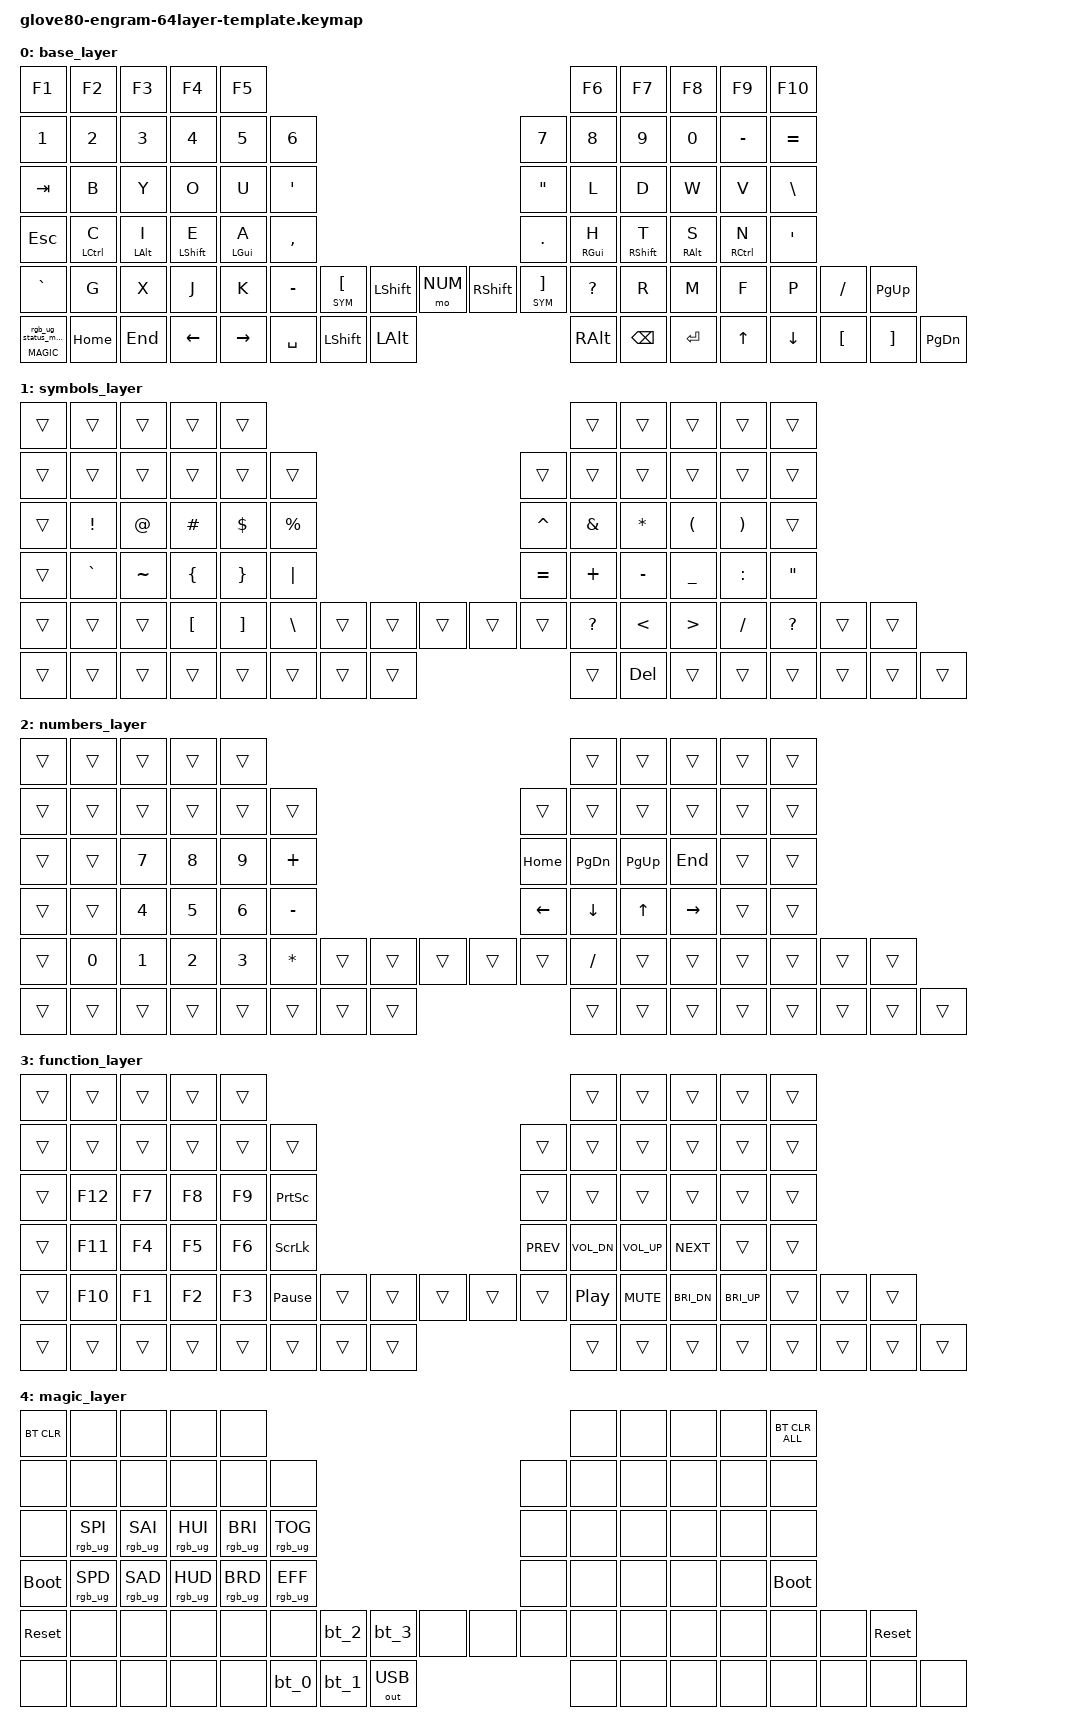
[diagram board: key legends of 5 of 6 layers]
/*
 * Glove80 Engram Layout with 64-Layer Support
 * Template for glove80-keymaps repo generation
 *
 * This template is designed to be:
 * 1. Generated/modified in glove80-keymaps repo using sunaku workflow
 * 2. Copied to zmk firmware repo at: app/boards/arm/glove80/glove80.keymap
 * 3. Built with 64-layer capable firmware
 *
 * WORKFLOW:
 * - Edit/generate in glove80-keymaps repo (with templating + PDF generation)
 * - Copy generated DTSI to ZMK firmware repo
 * - Build with: nix-build -A glove80_combined
 *
 * COMPATIBILITY:
 * - Works with MoErgo web configurator format
 * - Supports up to 64 layers (layers 0-63)
 * - Preserves factory behaviors for bootloader/reset access
 */

#include <behaviors.dtsi>
#include <dt-bindings/zmk/keys.h>
#include <dt-bindings/zmk/bt.h>
#include <dt-bindings/zmk/ext_power.h>
#include <dt-bindings/zmk/outputs.h>
#include <dt-bindings/zmk/rgb.h>

// Layer definitions - Engram optimized
#define BASE     0  // Engram base layer
#define SYM      1  // Symbols layer
#define NUM      2  // Numbers/navigation layer
#define FN       3  // Function keys
#define MAGIC    4  // System: Bootloader, reset, RGB, Bluetooth

// Example extended layers (you can use up to layer 63!)
#define GREEK    5  // Greek letters (example)
#define MATH     6  // Math symbols (example)
#define MEDIA    7  // Media controls (example)
// ... define up to layer 63 as needed

/ {
    /*
     * BEHAVIORS
     * Define custom behaviors for your layout
     */
    behaviors {
        // Home row mods - balanced for Engram
        hml: homerow_mods_left {
            compatible = "zmk,behavior-hold-tap";
            #binding-cells = <2>;
            flavor = "balanced";
            tapping-term-ms = <280>;
            quick-tap-ms = <175>;
            require-prior-idle-ms = <150>;
            bindings = <&kp>, <&kp>;
            hold-trigger-key-positions = <
                // Right hand keys (allow left hand mods)
                5 6 7 8 9
                15 16 17 18 19 20
                25 26 27 28 29 30
                35 36 37 38 39 40
                50 51 52 53 54 55
                60 61 62 63 64 65
                69 70 71 72 73 74 75 76 77 78 79
            >;
        };

        hmr: homerow_mods_right {
            compatible = "zmk,behavior-hold-tap";
            #binding-cells = <2>;
            flavor = "balanced";
            tapping-term-ms = <280>;
            quick-tap-ms = <175>;
            require-prior-idle-ms = <150>;
            bindings = <&kp>, <&kp>;
            hold-trigger-key-positions = <
                // Left hand keys (allow right hand mods)
                0 1 2 3 4
                10 11 12 13 14
                21 22 23 24
                31 32 33 34
                41 42 43 44 45 46 47 48 49
                56 57 58 59
                66 67 68
            >;
        };

        // Layer tap for symbol/number access
        ltq: layer_tap_quick {
            compatible = "zmk,behavior-hold-tap";
            #binding-cells = <2>;
            flavor = "balanced";
            tapping-term-ms = <200>;
            quick-tap-ms = <150>;
            bindings = <&mo>, <&kp>;
        };

        // Magic layer access (for system functions)
        magic: magic_hold_tap {
            compatible = "zmk,behavior-hold-tap";
            #binding-cells = <2>;
            flavor = "tap-preferred";
            tapping-term-ms = <200>;
            bindings = <&mo>, <&rgb_ug_status_macro>;
        };
    };

    /*
     * MACROS
     * Define macros for common operations
     */
    macros {
        // RGB status display
        rgb_ug_status_macro: rgb_ug_status_macro_0 {
            compatible = "zmk,behavior-macro";
            #binding-cells = <0>;
            bindings = <&rgb_ug RGB_STATUS>;
        };

        // Bluetooth profile selection macros
        bt_0: bt_profile_macro_0 {
            compatible = "zmk,behavior-macro";
            #binding-cells = <0>;
            bindings = <&out OUT_BLE>, <&bt BT_SEL 0>;
        };

        bt_1: bt_profile_macro_1 {
            compatible = "zmk,behavior-macro";
            #binding-cells = <0>;
            bindings = <&out OUT_BLE>, <&bt BT_SEL 1>;
        };

        bt_2: bt_profile_macro_2 {
            compatible = "zmk,behavior-macro";
            #binding-cells = <0>;
            bindings = <&out OUT_BLE>, <&bt BT_SEL 2>;
        };

        bt_3: bt_profile_macro_3 {
            compatible = "zmk,behavior-macro";
            #binding-cells = <0>;
            bindings = <&out OUT_BLE>, <&bt BT_SEL 3>;
        };
    };

    /*
     * KEYMAP
     * Engram layout with 64-layer support
     */
    keymap {
        compatible = "zmk,keymap";

        // =================================================================
        // LAYER 0: BASE (Engram)
        // =================================================================
        /*
         * Engram Layout:
         * https://engram.dev/
         *
         *     b  y  o  u  '     "  l  d  w  v
         *     c  i  e  a  ,     .  h  t  s  n
         *     g  x  j  k  -     ?  r  m  f  p
         *        ␣  ⇧  ⎇        ⎈  ⌫  ↵
         *
         * With home row mods:
         * Left:  C(c) A(i) S(e) G(a)
         * Right: G(h) S(t) A(s) C(n)
         */
        base_layer {
            bindings = <
            // Top row (F-keys remain for compatibility)
            &kp F1         &kp F2          &kp F3          &kp F4          &kp F5                                                                                                      &kp F6          &kp F7          &kp F8          &kp F9          &kp F10
            // Number row
            &kp N1         &kp N2          &kp N3          &kp N4          &kp N5          &kp N6                                                                          &kp N7          &kp N8          &kp N9          &kp N0          &kp MINUS       &kp EQUAL
            // Top letter row: B Y O U '  |  " L D W V
            &kp TAB        &kp B           &kp Y           &kp O           &kp U           &kp SQT                                                                         &kp DQT         &kp L           &kp D           &kp W           &kp V           &kp BSLH
            // Home row: C I E A ,  |  . H T S N (with home row mods)
            &kp ESC        &hml LCTRL C    &hml LALT I     &hml LSHFT E    &hml LGUI A     &kp COMMA                                                                       &kp DOT         &hmr RGUI H     &hmr RSHFT T    &hmr RALT S     &hmr RCTRL N    &kp SQT
            // Bottom row: G X J K -  |  ? R M F P
            &kp GRAVE      &kp G           &kp X           &kp J           &kp K           &kp MINUS       &ltq SYM LBKT   &kp LSHFT       &mo NUM         &kp RSHFT       &ltq SYM RBKT   &kp QMARK       &kp R           &kp M           &kp F           &kp P           &kp FSLH        &kp PG_UP
            // Thumb cluster
            &magic MAGIC 0 &kp HOME        &kp END         &kp LEFT        &kp RIGHT                       &kp SPACE       &kp LSHFT       &kp LALT        &kp RALT        &kp BSPC        &kp RET                                         &kp UP          &kp DOWN        &kp LBKT        &kp RBKT        &kp PG_DN
            >;
        };

        // =================================================================
        // LAYER 1: SYMBOLS
        // =================================================================
        /*
         * Optimized symbol layer for programming
         */
        symbols_layer {
            bindings = <
            &trans         &trans          &trans          &trans          &trans                                                                                                      &trans          &trans          &trans          &trans          &trans
            &trans         &trans          &trans          &trans          &trans          &trans                                                                          &trans          &trans          &trans          &trans          &trans          &trans
            &trans         &kp EXCL        &kp AT          &kp HASH        &kp DLLR        &kp PRCNT                                                                       &kp CARET       &kp AMPS        &kp STAR        &kp LPAR        &kp RPAR        &trans
            &trans         &kp GRAVE       &kp TILDE       &kp LBRC        &kp RBRC        &kp PIPE                                                                        &kp EQUAL       &kp PLUS        &kp MINUS       &kp UNDER       &kp COLON       &kp DQT
            &trans         &trans          &trans          &kp LBKT        &kp RBKT        &kp BSLH        &trans          &trans          &trans          &trans          &trans          &kp QMARK       &kp LT          &kp GT          &kp FSLH        &kp QMARK       &trans          &trans
            &trans         &trans          &trans          &trans          &trans                          &trans          &trans          &trans          &trans          &kp DEL         &trans                                          &trans          &trans          &trans          &trans          &trans
            >;
        };

        // =================================================================
        // LAYER 2: NUMBERS & NAVIGATION
        // =================================================================
        /*
         * Number pad + navigation
         */
        numbers_layer {
            bindings = <
            &trans         &trans          &trans          &trans          &trans                                                                                                      &trans          &trans          &trans          &trans          &trans
            &trans         &trans          &trans          &trans          &trans          &trans                                                                          &trans          &trans          &trans          &trans          &trans          &trans
            &trans         &trans          &kp N7          &kp N8          &kp N9          &kp PLUS                                                                        &kp HOME        &kp PG_DN       &kp PG_UP       &kp END         &trans          &trans
            &trans         &trans          &kp N4          &kp N5          &kp N6          &kp MINUS                                                                       &kp LEFT        &kp DOWN        &kp UP          &kp RIGHT       &trans          &trans
            &trans         &kp N0          &kp N1          &kp N2          &kp N3          &kp STAR        &trans          &trans          &trans          &trans          &trans          &kp FSLH        &trans          &trans          &trans          &trans          &trans          &trans
            &trans         &trans          &trans          &trans          &trans                          &trans          &trans          &trans          &trans          &trans          &trans                                          &trans          &trans          &trans          &trans          &trans
            >;
        };

        // =================================================================
        // LAYER 3: FUNCTION KEYS
        // =================================================================
        /*
         * Function keys and media controls
         */
        function_layer {
            bindings = <
            &trans         &trans          &trans          &trans          &trans                                                                                                      &trans          &trans          &trans          &trans          &trans
            &trans         &trans          &trans          &trans          &trans          &trans                                                                          &trans          &trans          &trans          &trans          &trans          &trans
            &trans         &kp F12         &kp F7          &kp F8          &kp F9          &kp PSCRN                                                                       &trans          &trans          &trans          &trans          &trans          &trans
            &trans         &kp F11         &kp F4          &kp F5          &kp F6          &kp SLCK                                                                        &kp C_PREV      &kp C_VOL_DN    &kp C_VOL_UP    &kp C_NEXT      &trans          &trans
            &trans         &kp F10         &kp F1          &kp F2          &kp F3          &kp PAUSE_BREAK &trans          &trans          &trans          &trans          &trans          &kp C_PP        &kp C_MUTE      &kp C_BRI_DN    &kp C_BRI_UP    &trans          &trans          &trans
            &trans         &trans          &trans          &trans          &trans                          &trans          &trans          &trans          &trans          &trans          &trans                                          &trans          &trans          &trans          &trans          &trans
            >;
        };

        // =================================================================
        // LAYER 4: MAGIC (System controls)
        // =================================================================
        /*
         * CRITICAL LAYER: Bootloader, reset, Bluetooth, RGB
         * DO NOT REMOVE - Required for firmware updates!
         */
        magic_layer {
            bindings = <
            &bt BT_CLR     &none           &none           &none           &none                                                                                                       &none           &none           &none           &none           &bt BT_CLR_ALL
            &none          &none           &none           &none           &none           &none                                                                           &none           &none           &none           &none           &none           &none
            &none          &rgb_ug RGB_SPI &rgb_ug RGB_SAI &rgb_ug RGB_HUI &rgb_ug RGB_BRI &rgb_ug RGB_TOG                                                                 &none           &none           &none           &none           &none           &none
            &bootloader    &rgb_ug RGB_SPD &rgb_ug RGB_SAD &rgb_ug RGB_HUD &rgb_ug RGB_BRD &rgb_ug RGB_EFF                                                                 &none           &none           &none           &none           &none           &bootloader
            &sys_reset     &none           &none           &none           &none           &none           &bt_2           &bt_3           &none           &none           &none           &none           &none           &none           &none           &none           &none           &sys_reset
            &none          &none           &none           &none           &none                           &bt_0           &bt_1           &out OUT_USB    &none           &none           &none                                           &none           &none           &none           &none           &none
            >;
        };

        // =================================================================
        // LAYERS 5-63: Extended layers (examples)
        // =================================================================
        /*
         * You can define up to 64 total layers (0-63)
         * Below are placeholder examples - customize as needed
         */

        // Example: Greek letters layer
        greek_layer {
            bindings = <
            &trans &trans &trans &trans &trans                                                                                           &trans &trans &trans &trans &trans
            &trans &trans &trans &trans &trans &trans                                                                       &trans &trans &trans &trans &trans &trans
            &trans &trans &trans &trans &trans &trans                                                                       &trans &trans &trans &trans &trans &trans
            &trans &trans &trans &trans &trans &trans                                                                       &trans &trans &trans &trans &trans &trans
            &trans &trans &trans &trans &trans &trans &trans &trans &trans    &trans &trans &trans &trans &trans &trans &trans &trans &trans &trans
            &trans &trans &trans &trans &trans        &trans &trans &trans    &trans &trans &trans        &trans &trans &trans &trans &trans
            >;
        };

        // Add more layers as needed...
        // layer_6 through layer_63 can be defined here
    };
};
